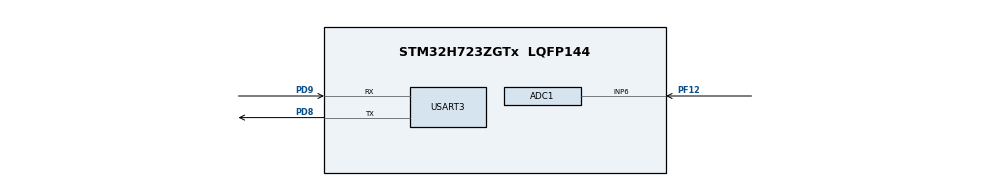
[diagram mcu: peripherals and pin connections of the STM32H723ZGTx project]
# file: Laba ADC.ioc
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ADC1.Channel-2\#ChannelRegularConversion=ADC_CHANNEL_6
ADC1.NbrOfConversionFlag=1
ADC1.OffsetNumber-2\#ChannelRegularConversion=ADC_OFFSET_NONE
ADC1.OffsetSignedSaturation-2\#ChannelRegularConversion=DISABLE
ADC1.Rank-2\#ChannelRegularConversion=1
ADC1.SamplingTime-2\#ChannelRegularConversion=ADC_SAMPLETIME_1CYCLE_5
ADC1.master=1
CORTEX_M7.default_mode_Activation=1
Mcu.Family=STM32H7
Mcu.Name=STM32H723ZGTx
Mcu.Package=LQFP144
NVIC.PriorityGroup=NVIC_PRIORITYGROUP_4
PC14-OSC32_IN.Mode=LSE-External-Oscillator
PC14-OSC32_IN.Signal=RCC_OSC32_IN
PC15-OSC32_OUT.Mode=LSE-External-Oscillator
PC15-OSC32_OUT.Signal=RCC_OSC32_OUT
PD8.Mode=Asynchronous
PD8.Signal=USART3_TX
PD9.Mode=Asynchronous
PD9.Signal=USART3_RX
PF12.Mode=IN6-Single-Ended
PF12.Signal=ADC1_INP6
PH0-OSC_IN.Mode=HSE-External-Oscillator
PH0-OSC_IN.Signal=RCC_OSC_IN
PH1-OSC_OUT.Mode=HSE-External-Oscillator
PH1-OSC_OUT.Signal=RCC_OSC_OUT
ProjectManager.HeapSize=0x200
ProjectManager.StackSize=0x400
ProjectManager.TargetToolchain=MDK-ARM V5.32
RCC.ADCFreq_Value=20000000
RCC.APB1Freq_Value=25000000
RCC.APB2Freq_Value=25000000
RCC.APB3Freq_Value=25000000
RCC.APB4Freq_Value=25000000
RCC.CortexFreq_Value=200000000
RCC.D1PPRE=RCC_APB3_DIV2
RCC.D2PPRE1=RCC_APB1_DIV2
RCC.D2PPRE2=RCC_APB2_DIV2
RCC.D3PPRE=RCC_APB4_DIV2
RCC.DIVM1=2
RCC.DIVM2=2
RCC.DIVN1=16
RCC.DIVN2=16
RCC.DIVP1=1
RCC.DIVP2=10
RCC.HCLKFreq_Value=50000000
RCC.HPRE=RCC_HCLK_DIV4
RCC.HSE_VALUE=25000000
RCC.PLL2FRACN=0
RCC.PLL3FRACN=0
RCC.PLLFRACN=0
RCC.PLLSourceVirtual=RCC_PLLSOURCE_HSE
RCC.SYSCLKFreq_VALUE=200000000
RCC.SYSCLKSource=RCC_SYSCLKSOURCE_PLLCLK
RCC.USBFreq_Value=100000000
USART3.VirtualMode-Asynchronous=VM_ASYNC
board=custom

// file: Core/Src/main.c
/* USER CODE BEGIN Header */
/**
  ******************************************************************************
  * @file           : main.c
  * @brief          : Main program body
  ******************************************************************************
  * @attention
  *
  * Copyright (c) 2022 STMicroelectronics.
  * All rights reserved.
  *
  * This software is licensed under terms that can be found in the LICENSE file
  * in the root directory of this software component.
  * If no LICENSE file comes with this software, it is provided AS-IS.
  *
  ******************************************************************************
  */
/* USER CODE END Header */
#include "main.h"

 ADC_HandleTypeDef hadc1;

UART_HandleTypeDef huart3;

void SystemClock_Config(void);
static void MPU_Config(void);
static void MX_GPIO_Init(void);
static void MX_ADC1_Init(void);
static void MX_USART3_UART_Init(void);

int main(void)
{

  /* MPU Configuration--------------------------------------------------------*/
  MPU_Config();

  /* MCU Configuration--------------------------------------------------------*/

  /* Reset of all peripherals, Initializes the Flash interface and the Systick. */
  HAL_Init();

  /* Configure the system clock */
  SystemClock_Config();

  /* Initialize all configured peripherals */
  MX_GPIO_Init();
  MX_ADC1_Init();
  MX_USART3_UART_Init();
  /* USER CODE BEGIN 2 */
	float voltage;
	char buffer[20];
	char buffer2[20]="Farmer\n";
	int size;

  /* USER CODE END 2 */

  /* Infinite loop */
  /* USER CODE BEGIN WHILE */
  while (1)
  {
		HAL_ADC_Start(&hadc1);

		HAL_ADC_PollForConversion(&hadc1,100);

		voltage=(float)(HAL_ADC_GetValue(&hadc1)*3.3f/65536);

		size=sprintf(buffer,"%.2f V\n\r",voltage);

		HAL_UART_Transmit(&huart3,(uint8_t*)buffer,size,100);

		HAL_UART_Transmit(&huart3,(uint8_t*)buffer2,size,100);
		HAL_Delay(1000);
    /* USER CODE END WHILE */

  }
}

void SystemClock_Config(void)
{
  RCC_OscInitTypeDef RCC_OscInitStruct = {0};
  RCC_ClkInitTypeDef RCC_ClkInitStruct = {0};

  /** Supply configuration update enable
  */
  HAL_PWREx_ConfigSupply(PWR_LDO_SUPPLY);

  /** Configure the main internal regulator output voltage
  */
  __HAL_PWR_VOLTAGESCALING_CONFIG(PWR_REGULATOR_VOLTAGE_SCALE2);

  while(!__HAL_PWR_GET_FLAG(PWR_FLAG_VOSRDY)) {}

  /** Macro to configure the PLL clock source
  */
  __HAL_RCC_PLL_PLLSOURCE_CONFIG(RCC_PLLSOURCE_HSE);

  /** Initializes the RCC Oscillators according to the specified parameters
  * in the RCC_OscInitTypeDef structure.
  */
  RCC_OscInitStruct.OscillatorType = RCC_OSCILLATORTYPE_HSE;
  RCC_OscInitStruct.HSEState = RCC_HSE_ON;
  RCC_OscInitStruct.PLL.PLLState = RCC_PLL_ON;
  RCC_OscInitStruct.PLL.PLLSource = RCC_PLLSOURCE_HSE;
  RCC_OscInitStruct.PLL.PLLM = 2;
  RCC_OscInitStruct.PLL.PLLN = 16;
  RCC_OscInitStruct.PLL.PLLP = 1;
  RCC_OscInitStruct.PLL.PLLQ = 2;
  RCC_OscInitStruct.PLL.PLLR = 2;
  RCC_OscInitStruct.PLL.PLLRGE = RCC_PLL1VCIRANGE_3;
  RCC_OscInitStruct.PLL.PLLVCOSEL = RCC_PLL1VCOWIDE;
  RCC_OscInitStruct.PLL.PLLFRACN = 0;
  if (HAL_RCC_OscConfig(&RCC_OscInitStruct) != HAL_OK)
  {
    Error_Handler();
  }

  /** Initializes the CPU, AHB and APB buses clocks
  */
  RCC_ClkInitStruct.ClockType = RCC_CLOCKTYPE_HCLK|RCC_CLOCKTYPE_SYSCLK
                              |RCC_CLOCKTYPE_PCLK1|RCC_CLOCKTYPE_PCLK2
                              |RCC_CLOCKTYPE_D3PCLK1|RCC_CLOCKTYPE_D1PCLK1;
  RCC_ClkInitStruct.SYSCLKSource = RCC_SYSCLKSOURCE_PLLCLK;
  RCC_ClkInitStruct.SYSCLKDivider = RCC_SYSCLK_DIV1;
  RCC_ClkInitStruct.AHBCLKDivider = RCC_HCLK_DIV4;
  RCC_ClkInitStruct.APB3CLKDivider = RCC_APB3_DIV2;
  RCC_ClkInitStruct.APB1CLKDivider = RCC_APB1_DIV2;
  RCC_ClkInitStruct.APB2CLKDivider = RCC_APB2_DIV2;
  RCC_ClkInitStruct.APB4CLKDivider = RCC_APB4_DIV2;

  if (HAL_RCC_ClockConfig(&RCC_ClkInitStruct, FLASH_LATENCY_0) != HAL_OK)
  {
    Error_Handler();
  }
}

static void MX_ADC1_Init(void)
{

  ADC_MultiModeTypeDef multimode = {0};
  ADC_ChannelConfTypeDef sConfig = {0};

  /** Common config
  */
  hadc1.Instance = ADC1;
  hadc1.Init.ClockPrescaler = ADC_CLOCK_ASYNC_DIV1;
  hadc1.Init.Resolution = ADC_RESOLUTION_16B;
  hadc1.Init.ScanConvMode = ADC_SCAN_DISABLE;
  hadc1.Init.EOCSelection = ADC_EOC_SINGLE_CONV;
  hadc1.Init.LowPowerAutoWait = DISABLE;
  hadc1.Init.ContinuousConvMode = DISABLE;
  hadc1.Init.NbrOfConversion = 1;
  hadc1.Init.DiscontinuousConvMode = DISABLE;
  hadc1.Init.ExternalTrigConv = ADC_SOFTWARE_START;
  hadc1.Init.ExternalTrigConvEdge = ADC_EXTERNALTRIGCONVEDGE_NONE;
  hadc1.Init.ConversionDataManagement = ADC_CONVERSIONDATA_DR;
  hadc1.Init.Overrun = ADC_OVR_DATA_PRESERVED;
  hadc1.Init.LeftBitShift = ADC_LEFTBITSHIFT_NONE;
  hadc1.Init.OversamplingMode = DISABLE;
  if (HAL_ADC_Init(&hadc1) != HAL_OK)
  {
    Error_Handler();
  }

  /** Configure the ADC multi-mode
  */
  multimode.Mode = ADC_MODE_INDEPENDENT;
  if (HAL_ADCEx_MultiModeConfigChannel(&hadc1, &multimode) != HAL_OK)
  {
    Error_Handler();
  }

  /** Configure Regular Channel
  */
  sConfig.Channel = ADC_CHANNEL_6;
  sConfig.Rank = ADC_REGULAR_RANK_1;
  sConfig.SamplingTime = ADC_SAMPLETIME_1CYCLE_5;
  sConfig.SingleDiff = ADC_SINGLE_ENDED;
  sConfig.OffsetNumber = ADC_OFFSET_NONE;
  sConfig.Offset = 0;
  sConfig.OffsetSignedSaturation = DISABLE;
  if (HAL_ADC_ConfigChannel(&hadc1, &sConfig) != HAL_OK)
  {
    Error_Handler();
  }

}

static void MX_USART3_UART_Init(void)
{

  huart3.Instance = USART3;
  huart3.Init.BaudRate = 115200;
  huart3.Init.WordLength = UART_WORDLENGTH_8B;
  huart3.Init.StopBits = UART_STOPBITS_1;
  huart3.Init.Parity = UART_PARITY_NONE;
  huart3.Init.Mode = UART_MODE_TX_RX;
  huart3.Init.HwFlowCtl = UART_HWCONTROL_NONE;
  huart3.Init.OverSampling = UART_OVERSAMPLING_16;
  huart3.Init.OneBitSampling = UART_ONE_BIT_SAMPLE_DISABLE;
  huart3.Init.ClockPrescaler = UART_PRESCALER_DIV1;
  huart3.AdvancedInit.AdvFeatureInit = UART_ADVFEATURE_NO_INIT;
  if (HAL_UART_Init(&huart3) != HAL_OK)
  {
    Error_Handler();
  }
  if (HAL_UARTEx_SetTxFifoThreshold(&huart3, UART_TXFIFO_THRESHOLD_1_8) != HAL_OK)
  {
    Error_Handler();
  }
  if (HAL_UARTEx_SetRxFifoThreshold(&huart3, UART_RXFIFO_THRESHOLD_1_8) != HAL_OK)
  {
    Error_Handler();
  }
  if (HAL_UARTEx_DisableFifoMode(&huart3) != HAL_OK)
  {
    Error_Handler();
  }

}

static void MX_GPIO_Init(void)
{

  /* GPIO Ports Clock Enable */
  __HAL_RCC_GPIOC_CLK_ENABLE();
  __HAL_RCC_GPIOH_CLK_ENABLE();
  __HAL_RCC_GPIOF_CLK_ENABLE();
  __HAL_RCC_GPIOD_CLK_ENABLE();

}

/* MPU Configuration */

void MPU_Config(void)
{
  MPU_Region_InitTypeDef MPU_InitStruct = {0};

  /* Disables the MPU */
  HAL_MPU_Disable();

  /** Initializes and configures the Region and the memory to be protected
  */
  MPU_InitStruct.Enable = MPU_REGION_ENABLE;
  MPU_InitStruct.Number = MPU_REGION_NUMBER0;
  MPU_InitStruct.BaseAddress = 0x0;
  MPU_InitStruct.Size = MPU_REGION_SIZE_4GB;
  MPU_InitStruct.SubRegionDisable = 0x87;
  MPU_InitStruct.TypeExtField = MPU_TEX_LEVEL0;
  MPU_InitStruct.AccessPermission = MPU_REGION_NO_ACCESS;
  MPU_InitStruct.DisableExec = MPU_INSTRUCTION_ACCESS_DISABLE;
  MPU_InitStruct.IsShareable = MPU_ACCESS_SHAREABLE;
  MPU_InitStruct.IsCacheable = MPU_ACCESS_NOT_CACHEABLE;
  MPU_InitStruct.IsBufferable = MPU_ACCESS_NOT_BUFFERABLE;

  HAL_MPU_ConfigRegion(&MPU_InitStruct);
  /* Enables the MPU */
  HAL_MPU_Enable(MPU_PRIVILEGED_DEFAULT);

}

void Error_Handler(void)
{
  __disable_irq();
  while (1)
  {
  }
}
